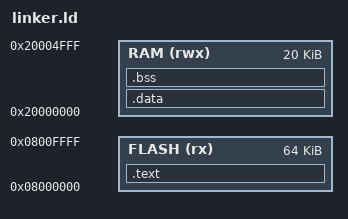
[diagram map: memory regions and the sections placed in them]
MEMORY
{
  FLASH (rx)  : ORIGIN = 0x08000000, LENGTH = 64K
  RAM   (rwx) : ORIGIN = 0x20000000, LENGTH = 20K
}

SECTIONS
{
  .text :
  {
    . = ALIGN(4);
    KEEP(*(.isr_vector))
    *(.text)
    *(.text*)
    *(.rodata)
    *(.rodata*)
    . = ALIGN(4);
    _sidata = .;
  } > FLASH

  _sdata = ORIGIN(RAM);
  .data : AT (_sidata)
  {
    . = ALIGN(4);
    _data = .;
    *(.data)
    *(.data*)
    . = ALIGN(4);
    _edata = .;
  } > RAM

  .bss :
  {
    . = ALIGN(4);
    _sbss = .;
    *(.bss)
    *(.bss*)
    *(COMMON)
    . = ALIGN(4);
    _ebss = .;
  } > RAM
}
